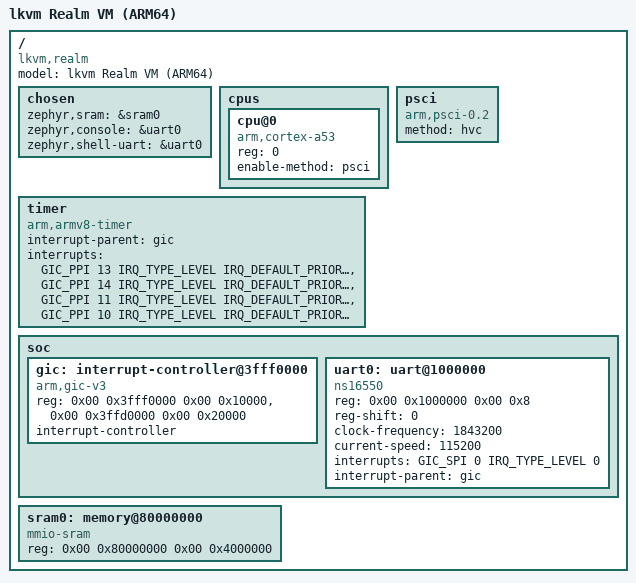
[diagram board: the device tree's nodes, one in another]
/dts-v1/;

#include <mem.h>
#include <arm64/armv8-a.dtsi>
#include <zephyr/dt-bindings/interrupt-controller/arm-gic.h>

/ {
	#address-cells = <2>;
	#size-cells = <2>;
	compatible = "lkvm,realm";
	model = "lkvm Realm VM (ARM64)";

	chosen {
		zephyr,sram = &sram0;
		zephyr,console = &uart0;
		zephyr,shell-uart = &uart0;
	};

	cpus {
		#address-cells = <1>;
		#size-cells = <0>;
		cpu@0 {
			device_type = "cpu";
			compatible = "arm,cortex-a53";
			reg = <0>;
			enable-method = "psci";
		};
	};

	psci {
		compatible = "arm,psci-0.2";
		method = "hvc";
	};

	timer {
		compatible = "arm,armv8-timer";
		interrupt-parent = <&gic>;
		interrupts = <GIC_PPI 13 IRQ_TYPE_LEVEL IRQ_DEFAULT_PRIORITY>,
			     <GIC_PPI 14 IRQ_TYPE_LEVEL IRQ_DEFAULT_PRIORITY>,
			     <GIC_PPI 11 IRQ_TYPE_LEVEL IRQ_DEFAULT_PRIORITY>,
			     <GIC_PPI 10 IRQ_TYPE_LEVEL IRQ_DEFAULT_PRIORITY>;
	};

	soc {
		#address-cells = <2>;
		#size-cells = <2>;
		ranges;

		/* GICv3 - driver compiled for ISR wrapper symbols, init has timeout for Realm */
		gic: interrupt-controller@3fff0000 {
			compatible = "arm,gic-v3", "arm,gic";
			reg = <0x00 0x3fff0000 0x00 0x10000>,
			      <0x00 0x3ffd0000 0x00 0x20000>;
			interrupt-controller;
			#interrupt-cells = <4>;
			#address-cells = <2>;
			#size-cells = <2>;
			status = "okay";
		};

		/* NS16550 UART at 0x1000000 - polling mode (UART_INTERRUPT_DRIVEN=n) */
		uart0: uart@1000000 {
			compatible = "ns16550";
			reg = <0x00 0x1000000 0x00 0x8>;
			reg-shift = <0>;
			clock-frequency = <1843200>;
			current-speed = <115200>;
			interrupts = <GIC_SPI 0 IRQ_TYPE_LEVEL 0>;
			interrupt-parent = <&gic>;
			status = "okay";
		};
	};

	/* Zephyr ARM64 generates an ARM64 image header with text_offset=0.
	 * lkvm reads the header → loads at ram_base + 0 = 0x80000000.
	 * Zephyr must link at 0x80000000 to match. */
	sram0: memory@80000000 {
		compatible = "mmio-sram";
		reg = <0x00 0x80000000 0x00 0x4000000>; /* 64MB */
	};
};
